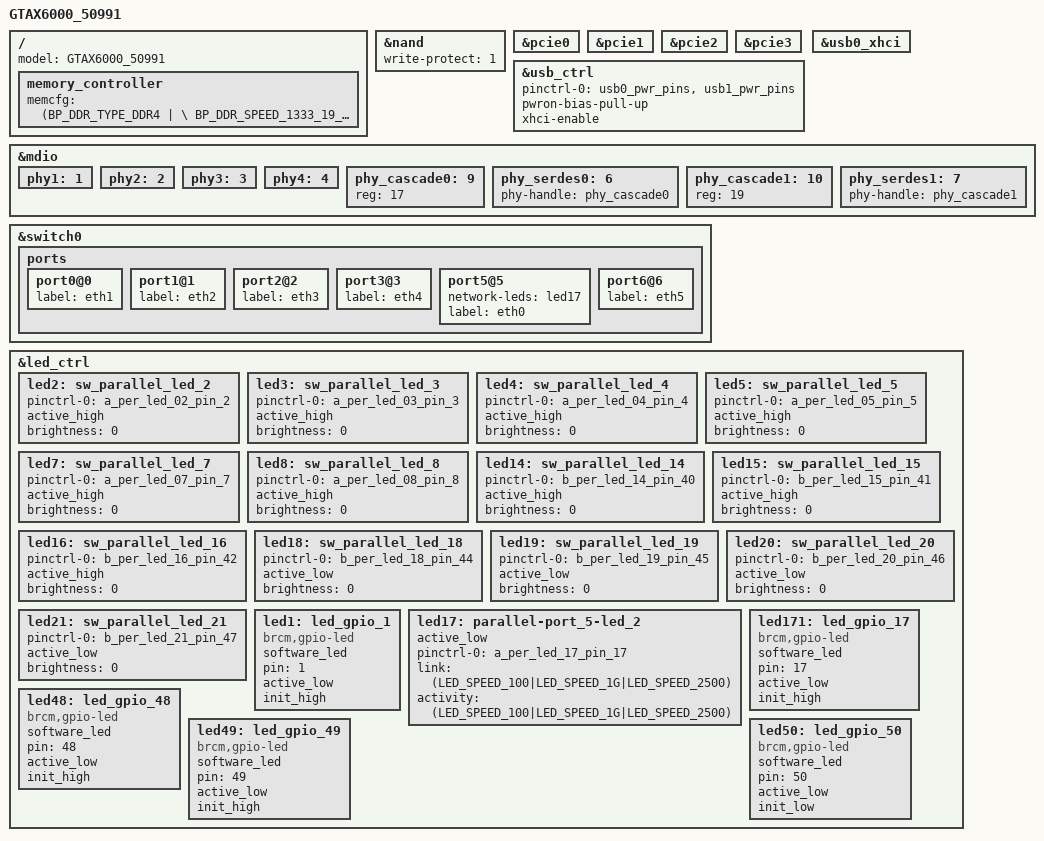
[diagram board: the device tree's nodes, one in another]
#include "4912.dtsi"

/ {
	model="GTAX6000_50991";

	memory_controller {
		memcfg = <(BP_DDR_TYPE_DDR4       | \
			BP_DDR_SPEED_1333_19_19_19    | \
			BP_DDR_TOTAL_SIZE_1024MB      | \
			BP_DDR_DEVICE_WIDTH_16        | \
			BP_DDR_TOTAL_WIDTH_32BIT      | \
			BP_DDR_TEMP_EXTENDED_ASR      | \
			BP_DDR_SSC_CONFIG_1)>;
	};
/*
    buttons: buttons {
        compatible = "brcm,buttons";
        // disable reset button for now. GPIO_51 seems trigger by itself
        // suggest to use another GPIO pin
	reset_button {
            ext_irq = <&bca_extintr 13 BCA_GPIO_ACTIVE_LOW (BCA_EXTINTR_TYPE_LOW_LEVEL | BCA_EXTINTR_TYPE_SENSE_EDGE)>;
            press {
                    print = "Button Press -- Hold for 5s to do restore to default";
            };
            hold {
                    rst_to_dflt = <5>;
            };
            release {
                    reset = <0>;
            };
        };
        ses_button {
            ext_irq = <&bca_extintr 12 BCA_GPIO_ACTIVE_LOW (BCA_EXTINTR_TYPE_LOW_LEVEL | BCA_EXTINTR_TYPE_SENSE_EDGE)>;
            release {
                    ses_short_period = <0>;
                    ses_long_period = <3>;
            };
        };
    };
*/
};

&nand {
	write-protect = <1>;
};
&pcie0 {
	status = "okay";
};
&pcie1 {
	status = "okay";
};
&pcie2 {
	status = "okay";
};
&pcie3 {
	status = "okay";
};

&usb_ctrl {
	pinctrl-names = "default";
	pinctrl-0 = <&usb0_pwr_pins &usb1_pwr_pins>;
	status = "okay";
	pwron-bias-pull-up;
	xhci-enable;
};

&usb0_xhci {
	status = "okay";
};

&mdio {
	phy1:1 {
		status = "okay";
	};

	phy2:2 {
		status = "okay";
	};

	phy3:3 {
		status = "okay";
	};

	phy4:4 {
		status = "okay";
	};


	phy_cascade0:9 {
		reg = <17>;
		status = "okay";
	};

	phy_serdes0:6 {
		phy-handle = <&phy_cascade0>;
		status = "okay";
	};

	phy_cascade1:10 {
		reg = <19>;
		status = "okay";
	};

	phy_serdes1:7 {
		phy-handle = <&phy_cascade1>;
		status = "okay";
	};

};

&switch0 {
	ports {
		port0@0 {
			status = "okay";
			label = "eth1";
		};

		port1@1 {
			status = "okay";
			label = "eth2";
		};

		port2@2 {
			status = "okay";
			label = "eth3";
		};

		port3@3 {
			status = "okay";
			label = "eth4";
		};

		port5@5 {
			network-leds = <&led17>;
			status = "okay";
			label = "eth0";
		};

		port6@6 {
			status = "okay";
			label = "eth5";
		};
/*
		port7@7 {
			status = "okay";
			label = "eth6";
		};
*/
	};
};

&led_ctrl {
	status="okay";

	/* CLED */
	/* LED_1A_R */
	led2: sw_parallel_led_2 {
		pinctrl-0 = <&a_per_led_02_pin_2>;
		active_high;
		status="okay";
		brightness = <0>;
	};
	/* LED_1A_B */
	led3: sw_parallel_led_3 {
		pinctrl-0 = <&a_per_led_03_pin_3>;
		active_high;
		status="okay";
		brightness = <0>;
	};
	/* LED_1A_G */
	led4: sw_parallel_led_4 {
		pinctrl-0 = <&a_per_led_04_pin_4>;
		active_high;
		status="okay";
		brightness = <0>;
	};

	/* LED_1B_R */
	led5: sw_parallel_led_5 {
		pinctrl-0 = <&a_per_led_05_pin_5>;
		active_high;
		status="okay";
		brightness = <0>;
	};
	/* LED_1B_B */
	led7: sw_parallel_led_7 {
		pinctrl-0 = <&a_per_led_07_pin_7>;
		active_high;
		status="okay";
		brightness = <0>;
	};
	/* LED_1B_G */
	led8: sw_parallel_led_8 {
		pinctrl-0 = <&a_per_led_08_pin_8>;
		active_high;
		status="okay";
		brightness = <0>;
	};

	/* LED_1C_R */
	led14: sw_parallel_led_14 {
		pinctrl-0 = <&b_per_led_14_pin_40>;
		active_high;
		status="okay";
		brightness = <0>;
	};
	/* LED_1C_B */
	led15: sw_parallel_led_15 {
		pinctrl-0 = <&b_per_led_15_pin_41>;
		active_high;
		status="okay";
		brightness = <0>;
	};
	/* LED_1C_G */
	led16: sw_parallel_led_16 {
		pinctrl-0 = <&b_per_led_16_pin_42>;
		active_high;
		status="okay";
		brightness = <0>;
	};

	/* LED_1D_R1 */
	led18: sw_parallel_led_18 {
		pinctrl-0 = <&b_per_led_18_pin_44>;
		active_low;
		status="okay";
		brightness = <0>;
	};
	/* LED_1D_R2 */
	led19: sw_parallel_led_19 {
		pinctrl-0 = <&b_per_led_19_pin_45>;
		active_low;
		status="okay";
		brightness = <0>;
	};
	/* LED_1D_R3 */
	led20: sw_parallel_led_20 {
		pinctrl-0 = <&b_per_led_20_pin_46>;
		active_low;
		status="okay";
		brightness = <0>;
	};
	/* LED_1D_R4 */
	led21: sw_parallel_led_21 {
		pinctrl-0 = <&b_per_led_21_pin_47>;
		active_low;
		status="okay";
		brightness = <0>;
	};

	/* GPIO LED */
	/* LAN LED */
	led1:led_gpio_1 {
		compatible = "brcm,gpio-led";
		software_led;
		pin = <1>;
		active_low;
		init_high;
	};

	/* 2.5G LED */
	led17:parallel-port_5-led_2 {
		active_low;
		pinctrl-0 = <&a_per_led_17_pin_17>;
		link = <(LED_SPEED_100|LED_SPEED_1G|LED_SPEED_2500)>;
		activity = <(LED_SPEED_100|LED_SPEED_1G|LED_SPEED_2500)>;
		status = "okay";
	};

	/* 2.5G LED GPIO mode */
	led171:led_gpio_17 {
		compatible = "brcm,gpio-led";
		software_led;
		pin = <17>;
		active_low;
		init_high;
	};

	/* WPS LED */
	led48:led_gpio_48 {
		compatible = "brcm,gpio-led";
		software_led;
		pin = <48>;
		active_low;
		init_high;
	};

	/* WAN Red LED */
	led49:led_gpio_49 {
		compatible = "brcm,gpio-led";
		software_led;
		pin = <49>;
		active_low;
		init_high;
	};

	/* Power LED */
	led50:led_gpio_50 {
		compatible = "brcm,gpio-led";
		software_led;
		pin = <50>;
		active_low;
		init_low;
	};
};
